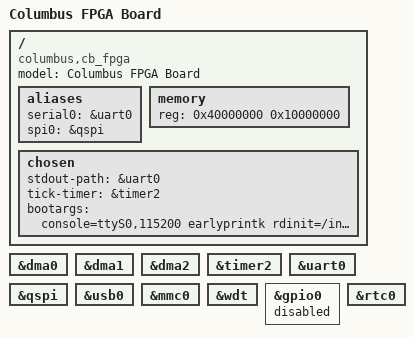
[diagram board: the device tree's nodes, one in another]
/dts-v1/;
#include "columbus.dtsi"

/*
* if override fields not set,use the default defined in columbus.dtsi
*/

/ {
	model = "Columbus FPGA Board";
	compatible = "columbus,cb_fpga";

	aliases {
		serial0 = &uart0;
		spi0 = &qspi;
	};

	memory {
		device_type = "memory";
		reg = <0x40000000 0x10000000>;
	};

	chosen {
		stdout-path = &uart0;
		tick-timer = &timer2;
		bootargs = "console=ttyS0,115200 earlyprintk rdinit=/init clk_ignore_unused";
	};


};

&dma0 {
       status = "okay";
};
&dma1 {
       status = "okay";
};
&dma2 {
       status = "okay";
};

&timer2 {
	status = "okay";
};

&uart0 {
	status = "okay";
};

&qspi {
	status = "okay";
};

&usb0 {
	status = "okay";
};

&mmc0 {
	status = "okay";
};

&wdt {
	status = "okay";
};

&gpio0 {
       status = "disabled";
};

&rtc0 {
       status = "okay";
};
